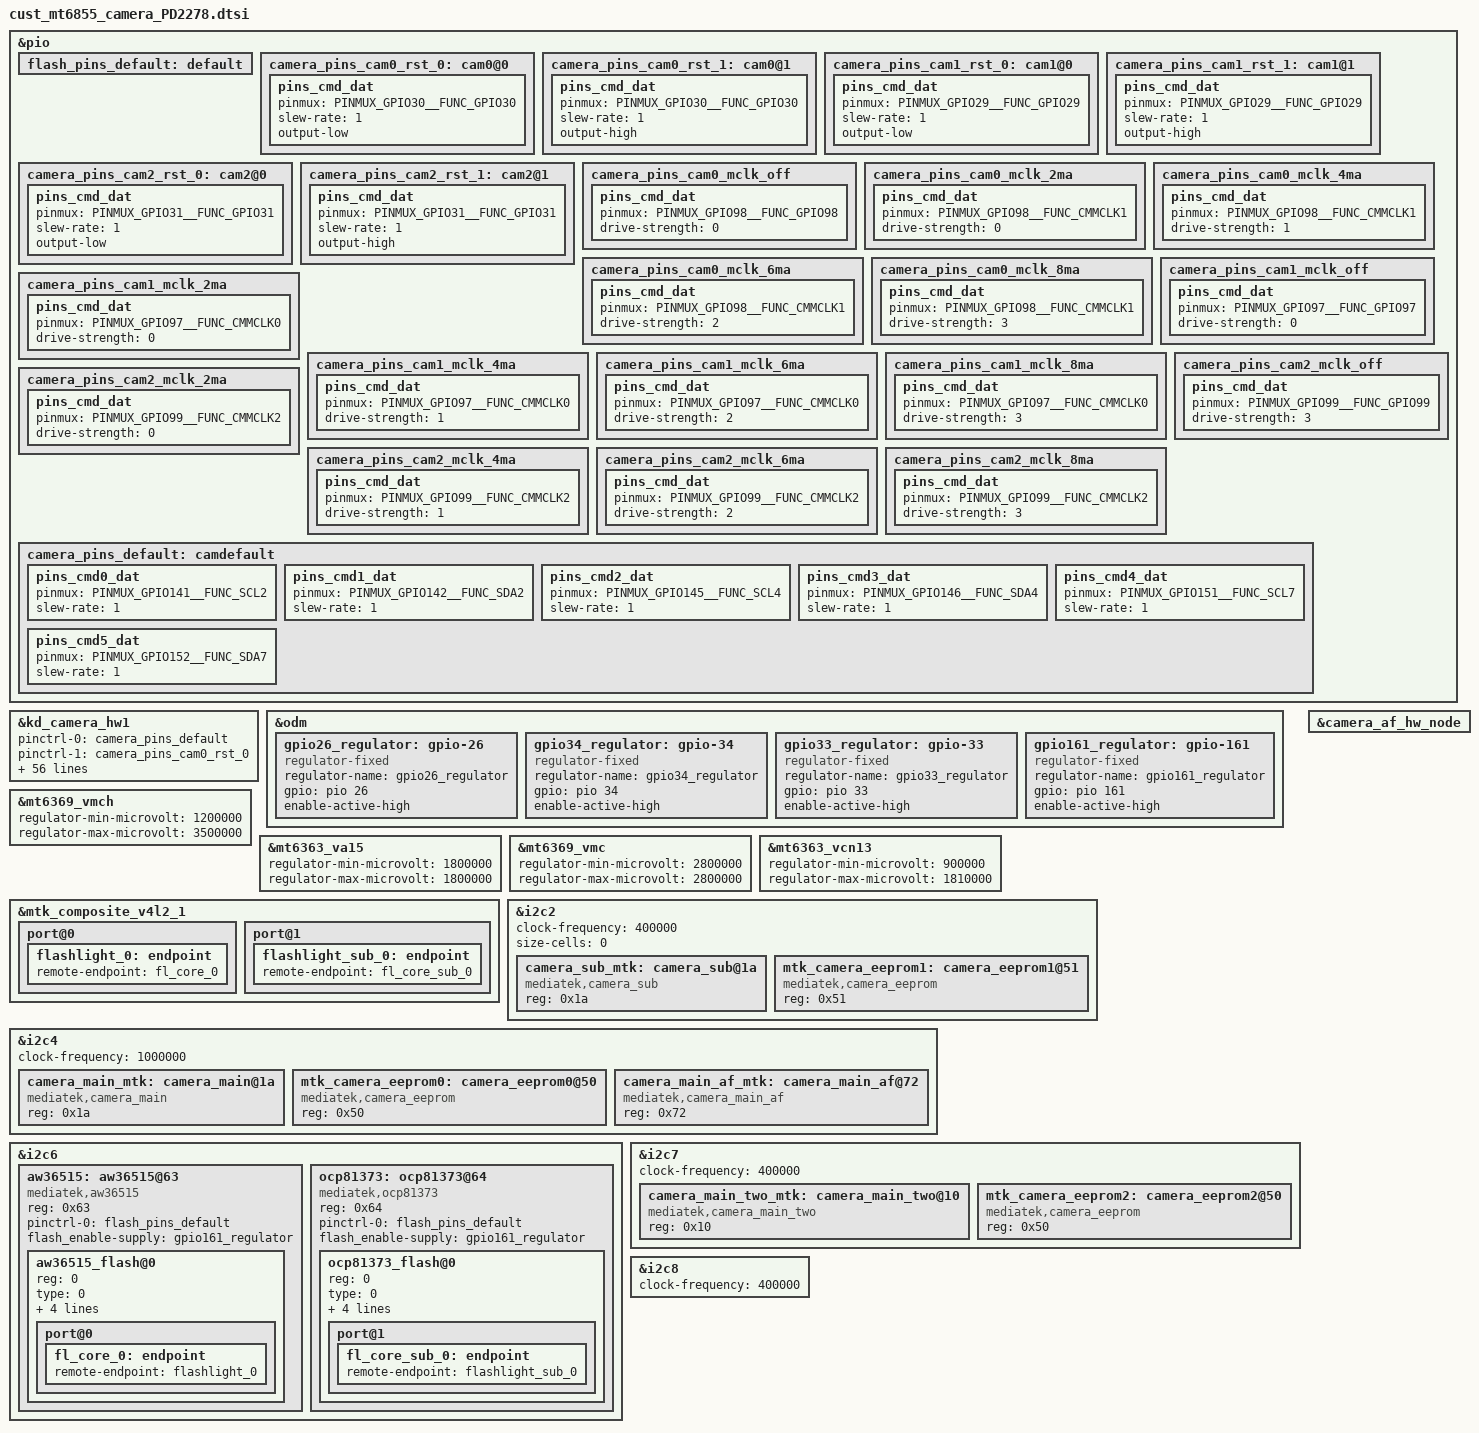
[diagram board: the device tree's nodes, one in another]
// SPDX-License-Identifier: GPL-2.0
/* Copyright (c) 2020 MediaTek Inc. */
/* CAMERA GPIO standardization */

/* flash led */
&pio {
	flash_pins_default: default {
	};
};
&pio {
	camera_pins_cam0_rst_0: cam0@0 {
		pins_cmd_dat {
			pinmux = <PINMUX_GPIO30__FUNC_GPIO30>;
			slew-rate = <1>;
			output-low;
		};
	};
	camera_pins_cam0_rst_1: cam0@1 {
		pins_cmd_dat {
			pinmux = <PINMUX_GPIO30__FUNC_GPIO30>;
			slew-rate = <1>;
			output-high;
		};
	};

	camera_pins_cam1_rst_0: cam1@0 {
		pins_cmd_dat {
			pinmux = <PINMUX_GPIO29__FUNC_GPIO29>;
			slew-rate = <1>;
			output-low;
		};
	};
	camera_pins_cam1_rst_1: cam1@1 {
		pins_cmd_dat {
			pinmux = <PINMUX_GPIO29__FUNC_GPIO29>;
			slew-rate = <1>;
			output-high;
		};
	};

	camera_pins_cam2_rst_0: cam2@0 {
		pins_cmd_dat {
			pinmux = <PINMUX_GPIO31__FUNC_GPIO31>;
			slew-rate = <1>;
			output-low;
		};
	};
	camera_pins_cam2_rst_1: cam2@1 {
		pins_cmd_dat {
			pinmux = <PINMUX_GPIO31__FUNC_GPIO31>;
			slew-rate = <1>;
			output-high;
		};
	};

	camera_pins_cam0_mclk_off: camera_pins_cam0_mclk_off {
		pins_cmd_dat {
			pinmux = <PINMUX_GPIO98__FUNC_GPIO98>;
			drive-strength = <0>;
		};
	};
	camera_pins_cam0_mclk_2ma: camera_pins_cam0_mclk_2ma {
		pins_cmd_dat {
			pinmux = <PINMUX_GPIO98__FUNC_CMMCLK1>;
			drive-strength = <0>;
		};
	};
	camera_pins_cam0_mclk_4ma: camera_pins_cam0_mclk_4ma {
		pins_cmd_dat {
			pinmux = <PINMUX_GPIO98__FUNC_CMMCLK1>;
			drive-strength = <1>;
		};
	};
	camera_pins_cam0_mclk_6ma: camera_pins_cam0_mclk_6ma {
		pins_cmd_dat {
			pinmux = <PINMUX_GPIO98__FUNC_CMMCLK1>;
			drive-strength = <2>;
		};
	};
	camera_pins_cam0_mclk_8ma: camera_pins_cam0_mclk_8ma {
		pins_cmd_dat {
			pinmux = <PINMUX_GPIO98__FUNC_CMMCLK1>;
			drive-strength = <3>;
		};
	};
	camera_pins_cam1_mclk_off: camera_pins_cam1_mclk_off {
		pins_cmd_dat {
			pinmux = <PINMUX_GPIO97__FUNC_GPIO97>;
			drive-strength = <0>;
		};
	};
	camera_pins_cam1_mclk_2ma: camera_pins_cam1_mclk_2ma {
		pins_cmd_dat {
			pinmux = <PINMUX_GPIO97__FUNC_CMMCLK0>;
			drive-strength = <0>;
		};
	};
	camera_pins_cam1_mclk_4ma: camera_pins_cam1_mclk_4ma {
		pins_cmd_dat {
			pinmux = <PINMUX_GPIO97__FUNC_CMMCLK0>;
			drive-strength = <1>;
		};
	};
	camera_pins_cam1_mclk_6ma: camera_pins_cam1_mclk_6ma {
		pins_cmd_dat {
			pinmux = <PINMUX_GPIO97__FUNC_CMMCLK0>;
			drive-strength = <2>;
		};
	};
	camera_pins_cam1_mclk_8ma: camera_pins_cam1_mclk_8ma {
		pins_cmd_dat {
			pinmux = <PINMUX_GPIO97__FUNC_CMMCLK0>;
			drive-strength = <3>;
		};
	};
	camera_pins_cam2_mclk_off: camera_pins_cam2_mclk_off {
		pins_cmd_dat {
			pinmux = <PINMUX_GPIO99__FUNC_GPIO99>;
			drive-strength = <3>;
		};
	};
	camera_pins_cam2_mclk_2ma: camera_pins_cam2_mclk_2ma {
		pins_cmd_dat {
			pinmux = <PINMUX_GPIO99__FUNC_CMMCLK2>;
			drive-strength = <0>;
		};
	};
	camera_pins_cam2_mclk_4ma: camera_pins_cam2_mclk_4ma {
		pins_cmd_dat {
			pinmux = <PINMUX_GPIO99__FUNC_CMMCLK2>;
			drive-strength = <1>;
		};
	};
	camera_pins_cam2_mclk_6ma: camera_pins_cam2_mclk_6ma {
		pins_cmd_dat {
			pinmux = <PINMUX_GPIO99__FUNC_CMMCLK2>;
			drive-strength = <2>;
		};
	};
	camera_pins_cam2_mclk_8ma: camera_pins_cam2_mclk_8ma {
		pins_cmd_dat {
			pinmux = <PINMUX_GPIO99__FUNC_CMMCLK2>;
			drive-strength = <3>;
		};
	};
	camera_pins_default: camdefault {
		pins_cmd0_dat {
			pinmux = <PINMUX_GPIO141__FUNC_SCL2>;
			slew-rate = <1>;
		};
		pins_cmd1_dat {
			pinmux = <PINMUX_GPIO142__FUNC_SDA2>;
			slew-rate = <1>;
		};
		pins_cmd2_dat {
			pinmux = <PINMUX_GPIO145__FUNC_SCL4>;
			slew-rate = <1>;
		};
		pins_cmd3_dat {
			pinmux = <PINMUX_GPIO146__FUNC_SDA4>;
			slew-rate = <1>;
		};
		pins_cmd4_dat {
			pinmux = <PINMUX_GPIO151__FUNC_SCL7>;
			slew-rate = <1>;
		};
		pins_cmd5_dat {
			pinmux = <PINMUX_GPIO152__FUNC_SDA7>;
			slew-rate = <1>;
		};
	};
};
&kd_camera_hw1 {
	pinctrl-names = "default",
			"cam0_rst0", "cam0_rst1",
			"cam1_rst0", "cam1_rst1",
			"cam2_rst0", "cam2_rst1",
			"cam0_mclk_off",
			"cam0_mclk_2mA", "cam0_mclk_4mA",
			"cam0_mclk_6mA", "cam0_mclk_8mA",
			"cam1_mclk_off",
			"cam1_mclk_2mA", "cam1_mclk_4mA",
			"cam1_mclk_6mA", "cam1_mclk_8mA",
			"cam2_mclk_off",
			"cam2_mclk_2mA", "cam2_mclk_4mA",
			"cam2_mclk_6mA", "cam2_mclk_8mA";
	pinctrl-0 = <&camera_pins_default>;
	pinctrl-1 = <&camera_pins_cam0_rst_0>;
	pinctrl-2 = <&camera_pins_cam0_rst_1>;
	pinctrl-3 = <&camera_pins_cam1_rst_0>;
	pinctrl-4 = <&camera_pins_cam1_rst_1>;
	pinctrl-5 = <&camera_pins_cam2_rst_0>;
	pinctrl-6 = <&camera_pins_cam2_rst_1>;
	pinctrl-7 = <&camera_pins_cam0_mclk_off>;
	pinctrl-8 = <&camera_pins_cam0_mclk_2ma>;
	pinctrl-9 = <&camera_pins_cam0_mclk_4ma>;
	pinctrl-10 = <&camera_pins_cam0_mclk_6ma>;
	pinctrl-11 = <&camera_pins_cam0_mclk_8ma>;
	pinctrl-12 = <&camera_pins_cam1_mclk_off>;
	pinctrl-13 = <&camera_pins_cam1_mclk_2ma>;
	pinctrl-14 = <&camera_pins_cam1_mclk_4ma>;
	pinctrl-15 = <&camera_pins_cam1_mclk_6ma>;
	pinctrl-16 = <&camera_pins_cam1_mclk_8ma>;
	pinctrl-17 = <&camera_pins_cam2_mclk_off>;
	pinctrl-18 = <&camera_pins_cam2_mclk_2ma>;
	pinctrl-19 = <&camera_pins_cam2_mclk_4ma>;
	pinctrl-20 = <&camera_pins_cam2_mclk_6ma>;
	pinctrl-21 = <&camera_pins_cam2_mclk_8ma>;

	/* main */
	cam0_vcama-supply = <&gpio34_regulator>;
	cam0_vcama1-supply = <&gpio26_regulator>;
	cam0_vcamd-supply = <&mt6363_vcn13>;
	cam0_vcamio-supply = <&mt6363_va15>;
	cam0_vcamaf_def-supply = <&mt6369_vmch>;

	/* front */
	cam1_vcama-supply = <&gpio26_regulator>;
	cam1_vcamd-supply = <&gpio33_regulator>;
	cam1_vcamd1-supply = <&mt6363_vcn13>;
	cam1_vcamio-supply = <&mt6363_va15>;

	/* main2 (depth) */
	cam2_vcama-supply = <&gpio26_regulator>;
	cam2_vcamio-supply = <&mt6363_va15>;

	cam0_enable_sensor = "s5kjnssq33pd2278_mipi_raw";
	cam1_enable_sensor = "s5k4h7pd2278_mipi_raw";
	cam2_enable_sensor = "gc02m1bpd2278_mipi_mono";

	cam0_pin_mclk = "mclk";
	cam0_pin_rst = "gpio";
	cam0_pin_vcama = "regulator";
	cam0_pin_vcama1 = "regulator";
	cam0_pin_vcamd = "regulator";
	cam0_pin_vcamd1 = "regulator";
	cam0_pin_vcamio = "regulator";
	cam0_pin_vcamaf_def = "regulator";
	cam1_pin_mclk = "mclk";
	cam1_pin_rst = "gpio";
	cam1_pin_vcama = "regulator";
	cam1_pin_vcama1 = "regulator";
	cam1_pin_vcamd = "regulator";
	cam1_pin_vcamd1 = "regulator";
	cam1_pin_vcamio = "regulator";
	cam2_pin_mclk = "mclk";
	cam2_pin_rst = "gpio";
	cam2_pin_vcama = "regulator";
	cam2_pin_vcama1 = "regulator";
	cam2_pin_vcamio = "regulator";

	gpio_nums = <6>;
	gpios = <145 146 141 142 151 152>;

	status = "okay";
};
&odm {
	gpio26_regulator:gpio-26 {
		compatible = "regulator-fixed";
		regulator-name = "gpio26_regulator";
		gpio = <&pio 26 0x0>;
		enable-active-high;
		status = "okay";
	};
	gpio34_regulator:gpio-34 {
		compatible = "regulator-fixed";
		regulator-name = "gpio34_regulator";
		gpio = <&pio 34 0x0>;
		enable-active-high;
		status = "okay";
	};
	gpio33_regulator:gpio-33 {
		compatible = "regulator-fixed";
		regulator-name = "gpio33_regulator";
		gpio = <&pio 33 0x0>;
		enable-active-high;
		status = "okay";
	};
	gpio161_regulator:gpio-161 {
		compatible = "regulator-fixed";
		regulator-name = "gpio161_regulator";
		gpio = <&pio 161 0x0>;
		enable-active-high;
		status = "okay";
	};
};
/* CAMERA GPIO end */
&mt6369_vmch{
	regulator-min-microvolt = <1200000>;
	regulator-max-microvolt = <3500000>;
};

&mt6363_va15{
	regulator-min-microvolt = <1800000>;
	regulator-max-microvolt = <1800000>;
};

&mt6369_vmc{
	regulator-min-microvolt = <2800000>;
	regulator-max-microvolt = <2800000>;
};

&mt6363_vcn13{
	regulator-min-microvolt = <900000>;
	regulator-max-microvolt = <1810000>;
};

&mtk_composite_v4l2_1 {
	port@0 {
		flashlight_0: endpoint {
			remote-endpoint = <&fl_core_0>;
		};
	};
	port@1 {
		flashlight_sub_0: endpoint {
			remote-endpoint = <&fl_core_sub_0>;
		};
	};
};
/* CAMERA EEPROM */
&i2c2 {
	status = "okay";
	clock-frequency = <400000>;
	#address-cells = <1>;
	size-cells = <0>;
	camera_sub_mtk:camera_sub@1a {
		compatible = "mediatek,camera_sub";
		#thermal-sensor-cells = <0>;
		reg = <0x1a>;
		status = "okay";
	};
	mtk_camera_eeprom1:camera_eeprom1@51 {
		compatible = "mediatek,camera_eeprom";
		reg = <0x51>;
		status = "okay";
	};
};
&i2c4 {
	status = "okay";
	clock-frequency = <1000000>;
	#address-cells = <1>;
	#size-cells = <0>;
	camera_main_mtk:camera_main@1a {
		compatible = "mediatek,camera_main";
		#thermal-sensor-cells = <0>;
		reg = <0x1a>;
		status = "okay";
	};
	mtk_camera_eeprom0:camera_eeprom0@50 {
		compatible = "mediatek,camera_eeprom";
		reg = <0x50>;
		status = "okay";
	};
	camera_main_af_mtk:camera_main_af@72 {
		compatible = "mediatek,camera_main_af";
		reg = <0x72>;
		status = "okay";
	};
};
&i2c6 {
	aw36515:aw36515@63 {
		compatible = "mediatek,aw36515";
		reg = <0x63>;
		#cooling-cells = <2>;
		pinctrl-names = "default";
		pinctrl-0 = <&flash_pins_default>;
		flash_enable-supply = <&gpio161_regulator>;
		status = "okay";
		aw36515_flash@0{
			reg = <0>;
			type = <0>;
			ct = <0>;
			part = <0>;
			factory_torch_brt = <100>;  //LED0:100mA, add for factory torch test:AT+BKSG=1
			factory_flash_brt = <1050>; //LED0:1050mA, add for factory flash test:AT+FLAMP=1,1
			port@0 {
				fl_core_0: endpoint {
					remote-endpoint = <&flashlight_0>;
				};
			};
		};
	};
	ocp81373:ocp81373@64 {
		compatible = "mediatek,ocp81373";
		reg = <0x64>;
		#cooling-cells = <2>;
		pinctrl-names = "default";
		pinctrl-0 = <&flash_pins_default>;
		flash_enable-supply = <&gpio161_regulator>;
		status = "okay";
		ocp81373_flash@0{
			reg = <0>;
			type = <0>;
			ct = <0>;
			part = <0>;
			factory_torch_brt = <100>;  //LED0:100mA, add for factory torch test:AT+BKSG=1
			factory_flash_brt = <1050>; //LED0:1050mA, add for factory flash test:AT+FLAMP=1,1
			port@1 {
				fl_core_sub_0: endpoint {
					remote-endpoint = <&flashlight_sub_0>;
				};
			};
		};
	};
};
&i2c7 {
	status = "okay";
	clock-frequency = <400000>;
	#address-cells = <1>;
	#size-cells = <0>;

	camera_main_two_mtk:camera_main_two@10 {
		compatible = "mediatek,camera_main_two";
		#thermal-sensor-cells = <0>;
		reg = <0x10>;
		status = "okay";
	};
	mtk_camera_eeprom2:camera_eeprom2@50 {
		compatible = "mediatek,camera_eeprom";
		reg = <0x50>;
		status = "okay";
	};
};
&i2c8 {
	status = "okay";
	clock-frequency = <400000>;
	#address-cells = <1>;
	#size-cells = <0>;

};
/* CAMERA EEPROM end */


// /* CAMERA TZ config */
// &thermal_zones {
// 	camera_main: camera_main {
// 		polling-delay = <1000>; /* milliseconds */
// 		polling-delay-passive = <0>; /* milliseconds */
// 		thermal-sensors = <&camera_main_mtk>;
// 	};
// 	camera_sub: camera_sub {
// 		polling-delay = <1000>; /* milliseconds */
// 		polling-delay-passive = <0>; /* milliseconds */
// 		thermal-sensors = <&camera_sub_mtk>;
// 	};
// 	camera_main_two: camera_main_two {
// 		polling-delay = <1000>; /* milliseconds */
// 		polling-delay-passive = <0>; /* milliseconds */
// 		thermal-sensors = <&camera_main_two_mtk>;
// 	};
// };
// /* CAMERA TZ config end */
/* camera af start */
&camera_af_hw_node {
	//camaf_m1_pmic-supply = <&mt6369_vmch>;
	status = "okay";
};
/* camera af end */
